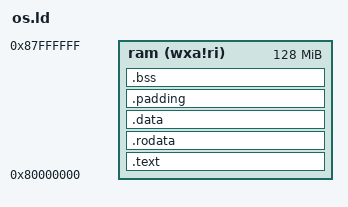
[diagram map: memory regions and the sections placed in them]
OUTPUT_ARCH( "riscv" )

ENTRY( _start )

# venus/src/rtl/venus/scheduler/scheduler_core_wrapper.sv
MEMORY
{
	ram   (wxa!ri) : ORIGIN = 0x80000000, LENGTH = 128M
}

SECTIONS
{
	.text : {
		PROVIDE(_text_start = .);
		. = 0x00000000;
		*(.startup)
		KEEP (*(.startup))
		. = 0x00000020;
		*(.startirq)
		KEEP (*(.startirq))
		*(.text .text.*)
		PROVIDE(_text_end = .);
	} >ram

	.rodata : {
		PROVIDE(_rodata_start = .);
		*(.rodata .rodata.*)
		*(.srodata .srodata.*)
		PROVIDE(_rodata_end = .);
	} >ram

	.data : {
		PROVIDE(_data_start = .);
		*(.sdata .sdata.*)
		*(.data .data.*)
		PROVIDE(_data_end = .);
	} >ram

# python end jacklight
	
	.padding :{
		*(.padding)
	} >ram
	
	.bss :{
		PROVIDE(_bss_start = .);
		*(.bss.stack)
		*(.sbss .sbss.*)
		*(.bss .bss.*)
		*(COMMON)
		PROVIDE(_bss_end = .);
	} >ram


	PROVIDE(_memory_start = ORIGIN(ram));
	PROVIDE(_memory_end = ORIGIN(ram) + LENGTH(ram));

	PROVIDE(_heap_start = _bss_end);
	PROVIDE(_heap_size = _memory_end - _heap_start);
}


